# MCSPI register map
Vendor: Texas Instruments
Peripheral module from a debugger description file (folder am335x).
Registers are 32-bit, access per field, no defined reset value unless marked. A register's access mark holds for its fields unless they carry their own. Offsets are as the file gives them; lines under a group give offsets from that group; [hi:lo] are bit positions; {n}, {i} and the like mark numbered series; 'fields as' and 'values as' point back to an identical list; <NAME> marks a mode.

## SPI
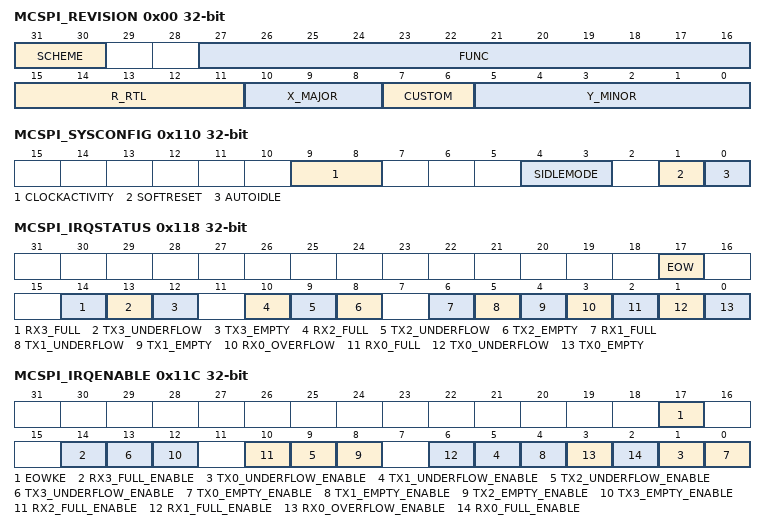
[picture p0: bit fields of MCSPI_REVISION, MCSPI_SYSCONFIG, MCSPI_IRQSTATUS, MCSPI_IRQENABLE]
0x00 MCSPI_REVISION — The McSPI system configuration register (MCSPI_REVISION) allows control of various parameters of the module interface. It is not sensitive to software reset.
  [31:30] SCHEME ro — Used to distinguish between old scheme and current.
  [27:16] FUNC ro — Function indicates a software compatible module family. If there is no level of software compatibility a new Func number (and hence REVISION) should be assigned.
  [15:11] R_RTL ro — R_RTL bit.
  [10:8] X_MAJOR ro — X_MAJOR bit.
  [7:6] CUSTOM rw — CUSTOM bit.
  [5:0] Y_MINOR rw — Y_MINOR bit.
0x110 MCSPI_SYSCONFIG — The McSPI system configuration register (MCSPI_SYSCONFIG) allows control of various parameters of the module interface. It is not sensitive to software reset.
  [9:8] CLOCKACTIVITY rw — Clocks activity during wake-up mode period.
  [4:3] SIDLEMODE rw — Power management.
  [1] SOFTRESET rw — Software reset. During reads it always returns 0.
  [0] AUTOIDLE rw — Internal OCP Clock gating strategy.
0x114 MCSPI_SYSSTATUS ro — The McSPI system status register (MCSPI_SYSSTATUS) provides status information about the module excluding the interrupt status information.
  [0] RESETDONE — Internal Reset Monitoring.
0x118 MCSPI_IRQSTATUS — The McSPI interrupt status register (MCSPI_IRQSTATUS) regroups all the status of the module internal events that can generate an interrupt.
  [17] EOW rw — End of word (EOW) count event when a channel is enabled using the FIFO buffer and the channel has sent the number of McSPI words defined by the MCSPI_XFERLEVEL[WCNT].
  [14] RX3_FULL rw — Receiver register is full or almost full. Only when Channel 3 is enabled. This bit indicate FIFO almost full status when built-in FIFO is used for receive register (MCSPI_CH3CONF[FFE3R] is set).
  [13] TX3_UNDERFLOW rw — Transmitter register underflow. Only when Channel 3 is enabled. The transmitter register is empty (not updated by Host or DMA with new data) before its time slot assignment. Exception: No TX_underflow event when no data has been loaded into the transmitter register since channel has been enabled.
  [12] TX3_EMPTY rw — Transmitter register is empty or almost empty. This bit indicate FIFO almost full status when built-in FIFO is used for transmit register (MCSPI_CH3CONF[FFE3W] is set). Note: Enabling the channel automatically raises this event.
  [10] RX2_FULL rw — Receiver register full or almost full. Channel 2 This bit indicate FIFO almost full status when built-in FIFO is used for receive register (MCSPI_CH3CONF[FFE2R] is set).
  [9] TX2_UNDERFLOW rw — Transmitter register underflow. Channel 2
  [8] TX2_EMPTY rw — Transmitter register empty or almost empty. Channel 2. This bit indicate FIFO almost full status when built-in FIFO is used for transmit register (MCSPI_CH3CONF[FFE2W] is set).
  [6] RX1_FULL rw — Receiver register full or almost full. Channel 1. This bit indicate FIFO almost full status when built-in FIFO is use for receive register (MCSPI_CH3CONF[FFE1R] is set).
  [5] TX1_UNDERFLOW rw — Transmitter register underflow. Channel 1.
  [4] TX1_EMPTY rw — Transmitter register empty or almost empty. Channel 1. This bit indicate FIFO almost full status when built-in FIFO is use for transmit register (MCSPI_CH3CONF[FFE1W] is set).
  [3] RX0_OVERFLOW rw — Receiver register overflow (slave mode only). Channel 0.
  [2] RX0_FULL rw — Receiver register full or almost full. Channel 0. Receiver register full or almost full. Channel 0
  [1] TX0_UNDERFLOW rw — Transmitter register underflow. Channel 0.
  [0] TX0_EMPTY rw — Transmitter register empty or almost empty. Channel 0. This bit indicate FIFO almost full status when built-in FIFO is use for transmit register (MCSPI_CH3CONF[FFE0W] is set).
0x11C MCSPI_IRQENABLE — This McSPI interrupt enable register (MCSPI_IRQENABLE) enables/disables the module internal sources of interrupt, on an event-by-event basis.
  [17] EOWKE rw — End of word count interrupt enable.
  [14] RX3_FULL_ENABLE rw — MCSPI_RX3 receiver register full or almost full interrupt enable (channel 3).
  [4n+1] TX{n}_UNDERFLOW_ENABLE rw (n=0..3) — MCSPI_TX{n} transmitter register underflow interrupt enable (channel {n}).
  [4n] TX{n}_EMPTY_ENABLE rw (n=0..3) — MCSPI_TX{n} transmitter register empty or almost empty interrupt enable (channel {n}).
  [10] RX2_FULL_ENABLE rw — MCSPI_RX2 receiver register full or almost full interrupt enable (channel 2).
  [6] RX1_FULL_ENABLE rw — MCSPI_RX1 receiver register full or almost full interrupt enable (channel 1)
  [3] RX0_OVERFLOW_ENABLE rw — MCSPI_RX0 receivier register overflow interrupt enable (channel 0).
  [2] RX0_FULL_ENABLE rw — MCSPI_RX0 receiver register full or almost full interrupt enable (channel 0).
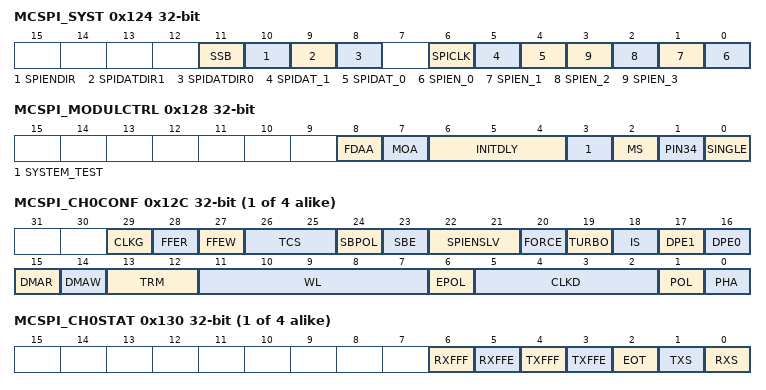
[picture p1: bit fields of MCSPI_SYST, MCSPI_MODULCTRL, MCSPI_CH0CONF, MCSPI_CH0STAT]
0x124 MCSPI_SYST — This McSPI system register (MCSPI_SYST) is used to configure the system interconnect either internally to the peripheral bus or externally to the device I/O pads, when the module is configured in the system test (SYSTEST) mode.
  [11] SSB rw — Set status bit. This bit must be cleared prior attempting to clear a status bit of the MCSPI_ IRQSTATUS register.
  [10] SPIENDIR rw — Sets the direction of the SPIEN[3:0] lines and SPICLK line.
  [9] SPIDATDIR1 rw — Sets the direction of the SPIDAT[1].
  [8] SPIDATDIR0 rw — Sets the direction of the SPIDAT[0].
  [6] SPICLK rw — SPICLK line (signal data value)
  [5] SPIDAT_1 rw — SPIDAT[1] line (signal data value)
  [4] SPIDAT_0 rw — SPIDAT[0] line (signal data value)
  [n] SPIEN_{n} rw (n=0..3) — SPIEN[{n}] line (signal data value)
0x128 MCSPI_MODULCTRL — This McSPI module control register (MCSPI_MODULCTRL) is used to configure the serial port interface.
  [8] FDAA rw — FIFO DMA Address 256 bit aligned. This register is used when a FIFO is managed by the module and DMA connected to the controller provides only 256 bit aligned address. If this bit is set the enabled channel which uses the FIFO has its datas managed through MCSPI_DAFTX and MCSPI_DAFRX registers instead of MCSPI_TX(i) and MCSPI_RX(i) registers.
  [7] MOA rw — Multiple word ocp access. This register can only be used when a channel is enabled using a FIFO. It allows the system to perform multiple SPI word access for a single 32 bit OCP word access. This is possible for WL less than 16.
  [6:4] INITDLY rw — Initial SPI delay for first transfer. This register is an option only available in SINGLE master mode, The controller waits for a delay to transmit the first SPI word after channel enabled and corresponding TX register filled. This delay is based on SPI output frequency clock, No clock output provided to the boundary and chip select is not active in 4 pin mode within this period.
  [3] SYSTEM_TEST rw — Enables the system test mode
  [2] MS rw — Master/ Slave
  [1] PIN34 rw — Pin mode selection. This register is used to configure the SPI pin mode, in master or slave mode. If asserted the controller only use SIMO,SOMI and SPICLK clock pin for SPI transfers.
  [0] SINGLE rw — Single channel / Multi Channel (master mode only).
{0x12C+0x14*i} MCSPI_CH{i}CONF (i=0..3) — The McSPI channel {i} configuration register (MCSPI_CH{i}CONF) is used to configure channel {i}.
  [29] CLKG rw — Clock divider granularity. This register defines the granularity of channel clock divider: power of two or one clock cycle granularity. When this bit is set the register MCSPI_CHCTRL[EXTCLK] must be configured to reach a maximum of 4096 clock divider ratio. Then The clock divider ratio is a concatenation of MCSPI_CHCONF[CLKD] and MCSPI_CHCTRL[EXTCLK] values.
  [28] FFER rw — FIFO enabled for receive. Only one channel can have this bit set.
  [27] FFEW rw — FIFO enabled for transmit. Only one channel can have this bit set.
  [26:25] TCS rw — Chip select time control. These two bits define the number of interface clock cycles between CS toggling and first or last edge of SPI clock.
  [24] SBPOL rw — Start bit polarity.
  [23] SBE rw — Start bit enable for SPI transfer.
  [22:21] SPIENSLV rw — Channel 0 only and slave mode only: SPI slave select signal detection. Reserved bits (read returns 0) for other cases.
  [20] FORCE rw — Manual SPIEN assertion to keep SPIEN active between SPI words (single channel master mode only).
  [19] TURBO rw — Turbo mode.
  [18] IS rw — Input select
  [17] DPE1 rw — Transmission enable for data line 1 (SPIDATAGZEN[1])
  [16] DPE0 rw — Transmission enable for data line 0 (SPIDATAGZEN[0])
  [15] DMAR rw — DMA read request. The DMA read request line is asserted when the channel is enabled and new data is available in the receive register of the channel. The DMA read request line is deasserted on read completion of the receive register of the channel.
  [14] DMAW rw — DMA write request. The DMA write request line is asserted when the channel is enabled and the MCSPI_TX{i} register of the channel is empty. The DMA write request line is deasserted on load completion of the MCSPI_TX{i} register of the channel.
  [13:12] TRM rw — Transmit/receive modes.
  [11:7] WL rw — SPI word length.
  [6] EPOL rw — SPIEN polarity
  [5:2] CLKD rw — Frequency divider for SPICLK (only when the module is a Master SPI device). A programmable clock divider divides the SPI reference clock (CLKSPIREF) with a 4 bit value, and results in a new clock SPICLK available to shift-in and shift-out data. By default the clock divider ratio has a power of two granularity when MCSPI_CHCONF[CLKG] is cleared, Otherwise this register is the 4 LSB bit of a 12 bit register concatenated with clock divider extension MCSPI_CHCTRL[EXTCLK] register. The value description below defines the clock ratio when MCSPI_CHCONF[CLKG] is cleared to 0.
  [1] POL rw — SPICLK polarity
  [0] PHA rw — SPICLK phase
{0x130+0x14*i} MCSPI_CH{i}STAT ro (i=0..3) — The McSPI channel {i} status register (MCSPI_CH{i}STAT) provides status information about the McSPI channel {i} FIFO transmit buffer register (MCSPI_TX{i}) and the McSPI channel {i} FIFO receive buffer register (MCSPI_RX{i}) of channel {i}.
  [6] RXFFF — Channel {i} FIFO receive buffer full status.
  [5] RXFFE — Channel {i} FIFO receive buffer empty status.
  [4] TXFFF — Channel {i} FIFO transmit buffer full status.
  [3] TXFFE — Channel {i} FIFO transmit buffer empty status.
  [2] EOT — Channel {i} end-of-transfer status. The definitions of beginning and end of transfer vary with master versus slave and the transfer format (transmit/receive mode, turbo mode).
  [1] TXS — Channel {i} transmitter register status. The bit is cleared when the host writes the most significant byte of the SPI word in the MCSPI_TX{i} register. The bit is set when enabling the channel {i} , and also when the SPI word is transferred from the MCSPI_TX{i} register to the shift register.
  [0] RXS — Channel {i} receiver register status. The bit is cleared when enabling the channel i, and also when the host reads the most significant byte of the received SPI word from the MCSPI_RX{i} register. The bit is set when the received SPI word is transferred from the shift register to the MCSPI_RX{i} register.
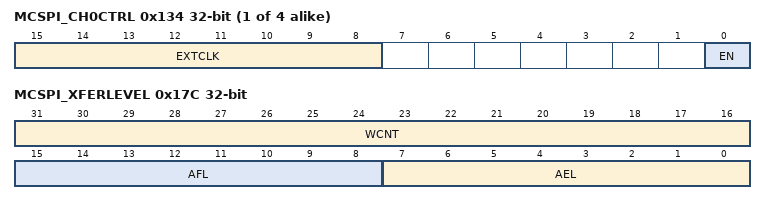
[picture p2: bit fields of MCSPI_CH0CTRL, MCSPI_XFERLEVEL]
{0x134+0x14*i} MCSPI_CH{i}CTRL (i=0..3)
  [15:8] EXTCLK rw — Clock ratio extension. Used to concatenate with the CLKD bit field in MCSPI_CH{i}CONF for clock ratio only when granularity is 1 clock cycle (CLKG bit in MCSPI_CH{i}CONF set to 1). Then the maximum value reached is a 4096 clock divider ratio.
  [0] EN rw — Channel {i} enable.
{0x138+0x14*i} MCSPI_TX{i} rw (i=0..3)
  [31:0] TDATA — Channel {i} data to transmit.
{0x13C+0x14*i} MCSPI_RX{i} ro (i=0..3) — The McSPI channel {i} FIFO receive buffer register (MCSPI_RX{i}) contains a single McSPI word received through the serial link. Little endian host access SPI 8 bit word on 0; big endian host accesses on 3h.
  [31:0] RDATA — Channel {i} received data.
0x17C MCSPI_XFERLEVEL rw — The McSPI transfer levels register (MCSPI_XFERLEVEL) provides the transfer levels needed while using the FIFO buffer during transfer.
  [31:16] WCNT — SPI word counter. Holds the programmable value of the number of SPI words to be transferred on the channel that is using the FIFO buffer. When the transfer has started, a read back of this register returns the current SPI word transfer index.
  [15:8] AFL — Buffer almost full. Holds the programmable almost full level value used to determine almost full buffer condition. If you want an interrupt or a DMA read request to be issued during a receive operation when the data buffer holds at least n bytes, then the buffer MCSPI_MODULCTRL[AFL] must be set with n - 1.
  [7:0] AEL — Buffer almost empty. Holds the programmable almost empty level value used to determine almost empty buffer condition. If you want an interrupt or a DMA write request to be issued during a transmit operation when the data buffer is able to receive n bytes, then the buffer MCSPI_MODULCTRL[AEL] must be set with n - 1.
0x180 MCSPI_DAFTX rw — The McSPI DMA address aligned FIFO transmitter register (MCSPI_DAFTX) contains the SPI words to transmit on the serial link when FIFO is used and the DMA address is aligned on 256 bit. This register is an image of one of the MCSPI_TX(i) registers corresponding to the channel which have its FIFO enabled. The SPI words are transferred with MSB first. See Chapter Access to data registers for the list of supported accesses.
  [31:0] DAFTDATA — FIFO Data to transmit with DMA 256 bit aligned address. This register is used only when MCSPI_MODULCTRL[FDAA] is set to 1, and only one of the MCSPI_CH(i)CONF[FFEW] of enabled channels is set. Without these conditions, any access to this register will return a null value.
0x1A0 MCSPI_DAFRX ro — The McSPI DMA address aligned FIFO receiver register (MCSPI_DAFRX) contains the SPI words to received on the serial link when FIFO used and DMA address is aligned on 256 bit. This register is an image of one of MCSPI_RX(i) register corresponding to the channel which have its FIFO enabled.
  [31:0] DAFRDATA — FIFO Received Data with DMA 256 bit aligned address. This register is used only when MCSPI_MODULCTRL[FDAA] is set to 1, and only one of the MCSPI_CH(i)CONF[FFER] of enabled channels is set. Without these conditions, any access to this register will return a null value.
